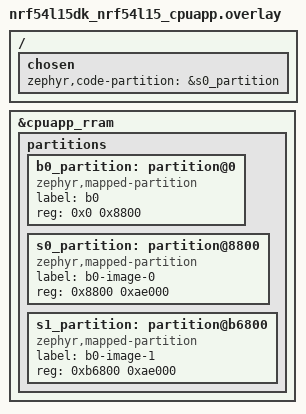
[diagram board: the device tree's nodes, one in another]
/*
 * Copyright (c) 2026 Nordic Semiconductor ASA
 *
 * SPDX-License-Identifier: LicenseRef-Nordic-5-Clause
 */

/delete-node/ &boot_partition;
/delete-node/ &slot0_partition;
/delete-node/ &slot1_partition;
/delete-node/ &storage_partition;

&cpuapp_rram {
	partitions {
		b0_partition: partition@0 {
			compatible = "zephyr,mapped-partition";
			label = "b0";
			reg = <0x0 0x8800>;
		};

		s0_partition: partition@8800 {
			compatible = "zephyr,mapped-partition";
			label = "b0-image-0";
			reg = <0x8800 0xae000>;
		};

		s1_partition: partition@b6800 {
			compatible = "zephyr,mapped-partition";
			label = "b0-image-1";
			reg = <0xb6800 0xae000>;
		};
	};
};

/ {
	chosen {
		zephyr,code-partition = &s0_partition;
	};
};
